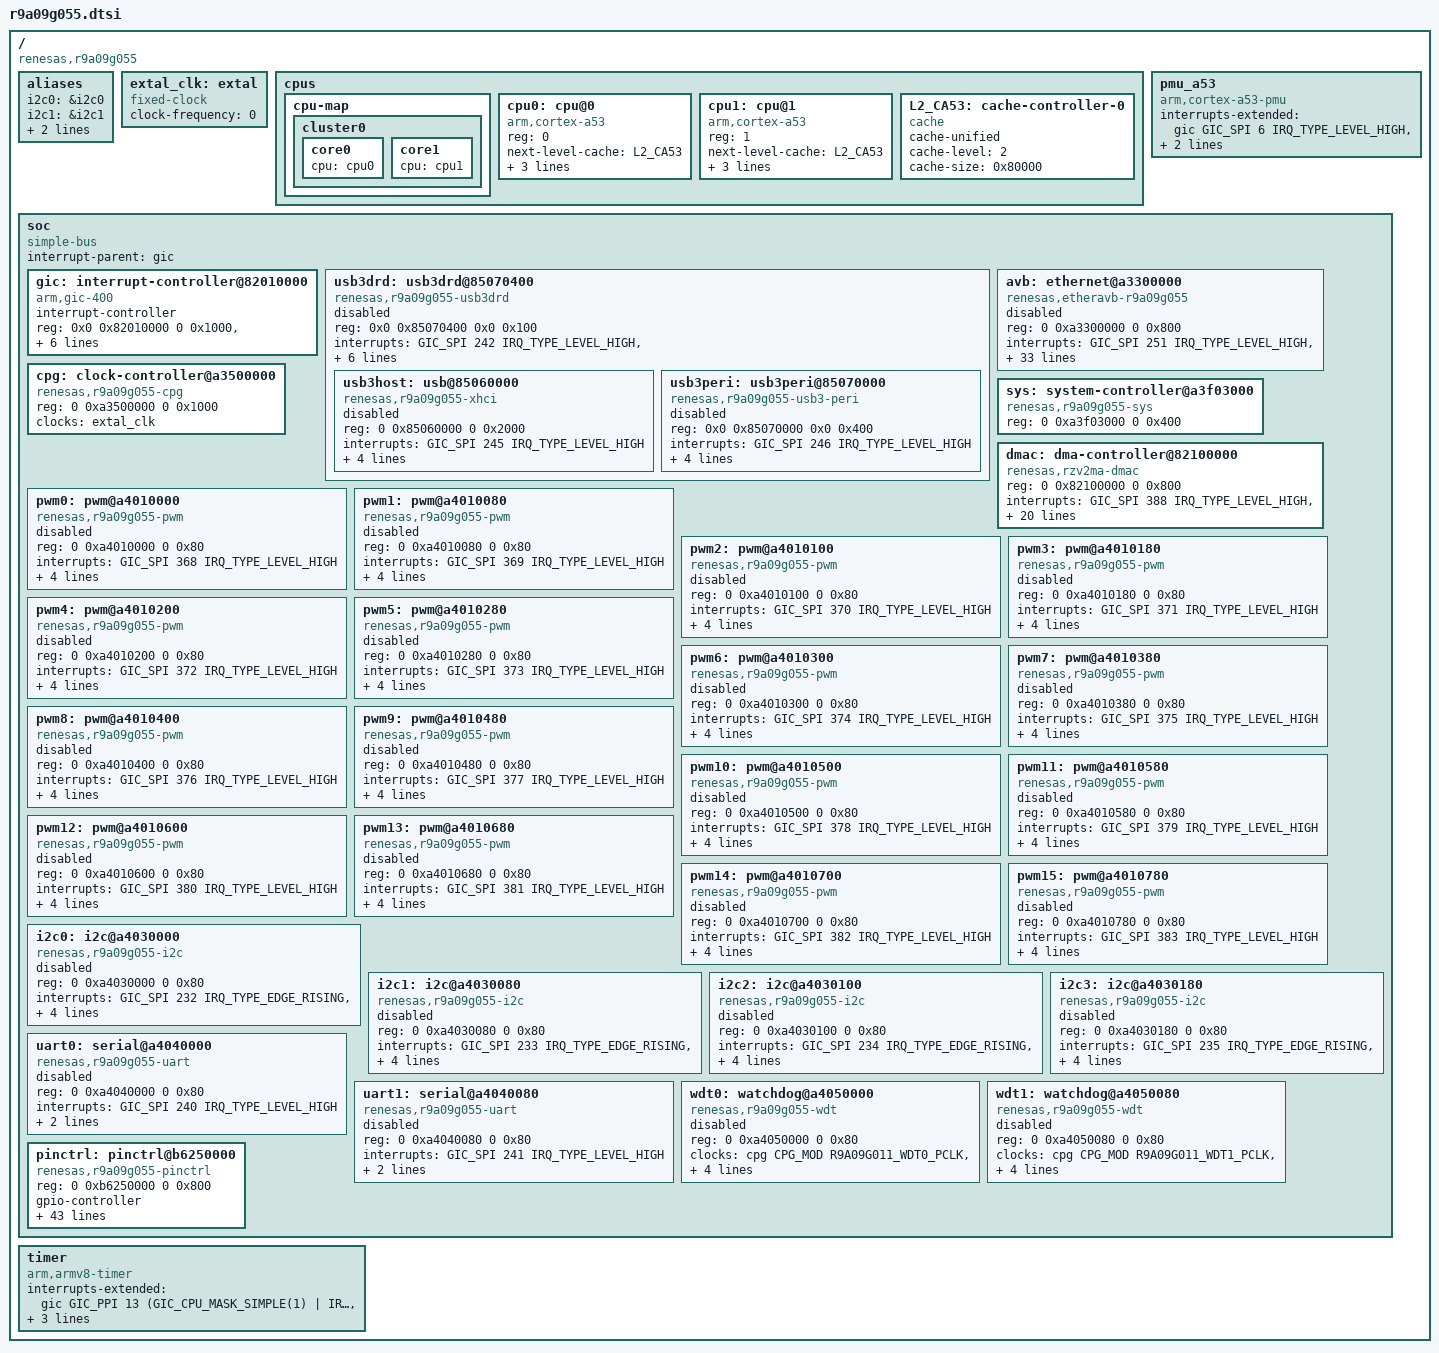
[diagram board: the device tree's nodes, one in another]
// SPDX-License-Identifier: (GPL-2.0-only OR BSD-2-Clause)
/*
 * Device Tree Source for the RZ/V2MA SoC
 *
 * Copyright (C) 2022 Renesas Electronics Corp.
 */

#include <dt-bindings/interrupt-controller/arm-gic.h>
#include <dt-bindings/clock/r9a09g011-cpg.h>

/memreserve/ 0x1B7FFF000 0x00001000; /* spin-table address */
/ {
	compatible = "renesas,r9a09g055";
	#address-cells = <2>;
	#size-cells = <2>;

        aliases {
                i2c0 = &i2c0;
                i2c1 = &i2c1;
                i2c2 = &i2c2;
                i2c3 = &i2c3;
        };

	/* clock can be either from exclk or crystal oscillator (XIN/XOUT) */
	extal_clk: extal {
		compatible = "fixed-clock";
		#clock-cells = <0>;
		/* This value must be overridden by the board */
		clock-frequency = <0>;
	};

	cpus {
		#address-cells = <1>;
		#size-cells = <0>;

		cpu-map {
			cluster0 {
				core0 {
					cpu = <&cpu0>;
				};
                                core1 {
                                        cpu = <&cpu1>;
                                };
			};
		};

		cpu0: cpu@0 {
			compatible = "arm,cortex-a53";
			reg = <0>;
			device_type = "cpu";
			next-level-cache = <&L2_CA53>;
			enable-method = "spin-table";
			cpu-release-addr = <0x1 0xB7FFF000>;
			clocks = <&cpg CPG_MOD R9A09G011_CA53_CLK>;
		};

                cpu1: cpu@1 {
                        compatible = "arm,cortex-a53";
                        reg = <1>;
                        device_type = "cpu";
			next-level-cache = <&L2_CA53>;
			enable-method = "spin-table";
			cpu-release-addr = <0x1 0xB7FFF000>;
                        clocks = <&cpg CPG_MOD R9A09G011_CA53_CLK>;
                };

		L2_CA53: cache-controller-0 {
			compatible = "cache";
			cache-unified;
			cache-level = <2>;
			cache-size = <0x80000>;
		};
	};

	pmu_a53 {
		compatible = "arm,cortex-a53-pmu";
        	interrupts-extended = <&gic GIC_SPI 6 IRQ_TYPE_LEVEL_HIGH>,
				      <&gic GIC_SPI 7 IRQ_TYPE_LEVEL_HIGH>;
        	interrupt-affinity = <&cpu0>,<&cpu1>;
    	};

	soc: soc {
		compatible = "simple-bus";
		interrupt-parent = <&gic>;
		#address-cells = <2>;
		#size-cells = <2>;
		ranges;

		gic: interrupt-controller@82010000 {
			compatible = "arm,gic-400";
			#interrupt-cells = <3>;
			#address-cells = <0>;
			interrupt-controller;
			reg = <0x0 0x82010000 0 0x1000>,
			      <0x0 0x82020000 0 0x20000>,
			      <0x0 0x82040000 0 0x20000>,
			      <0x0 0x82060000 0 0x20000>;
			interrupts = <GIC_PPI 9 (GIC_CPU_MASK_SIMPLE(1) | IRQ_TYPE_LEVEL_HIGH)>;
			clocks = <&cpg CPG_MOD R9A09G011_GIC_CLK>;
			clock-names = "clk";
		};

                usb3drd: usb3drd@85070400 {
                        compatible = "renesas,r9a09g055-usb3drd",
                                     "renesas,rzv2ma-usb3drd";
                        reg = <0x0 0x85070400 0x0 0x100>;
                        interrupts = <GIC_SPI 242 IRQ_TYPE_LEVEL_HIGH>,
                                     <GIC_SPI 243 IRQ_TYPE_LEVEL_HIGH>,
                                     <GIC_SPI 244 IRQ_TYPE_LEVEL_HIGH>;
                        interrupt-names = "drd", "bc", "gpi";
                        clocks = <&cpg CPG_MOD R9A09G011_USB_ACLK_P>,
                                 <&cpg CPG_MOD R9A09G011_USB_PCLK>;
                        clock-names = "axi", "reg";
                        resets = <&cpg R9A09G011_USB_DRD_RESET>;
                        power-domains = <&cpg>;
                        ranges;
                        #address-cells = <2>;
                        #size-cells = <2>;
                        status = "disabled";

                        usb3host: usb@85060000 {
                                compatible = "renesas,r9a09g055-xhci",
                                             "renesas,rzv2ma-xhci";
                                reg = <0 0x85060000 0 0x2000>;
                                interrupts = <GIC_SPI 245 IRQ_TYPE_LEVEL_HIGH>;
                                clocks = <&cpg CPG_MOD R9A09G011_USB_ACLK_H>,
                                         <&cpg CPG_MOD R9A09G011_USB_PCLK>;
                                clock-names = "axi", "reg";
                                resets = <&cpg R9A09G011_USB_ARESETN_H>;
                                power-domains = <&cpg>;
                                status = "disabled";
                        };

                        usb3peri: usb3peri@85070000 {
                                compatible = "renesas,r9a09g055-usb3-peri",
                                             "renesas,rzv2ma-usb3-peri";
                                reg = <0x0 0x85070000 0x0 0x400>;
                                interrupts = <GIC_SPI 246 IRQ_TYPE_LEVEL_HIGH>;
                                clocks = <&cpg CPG_MOD R9A09G011_USB_ACLK_P>,
                                         <&cpg CPG_MOD R9A09G011_USB_PCLK>;
                                clock-names = "axi", "reg";
                                resets = <&cpg R9A09G011_USB_ARESETN_P>;
                                power-domains = <&cpg>;
                                status = "disabled";
                        };
                };

		avb: ethernet@a3300000 {
			compatible = "renesas,etheravb-r9a09g055","renesas,etheravb-rzv2ma";
			reg = <0 0xa3300000 0 0x800>;
			interrupts = <GIC_SPI 251 IRQ_TYPE_LEVEL_HIGH>, /* ch0: Rx0 BE */
				     <GIC_SPI 252 IRQ_TYPE_LEVEL_HIGH>, /* ch1: Rx1 NC */
				     <GIC_SPI 253 IRQ_TYPE_LEVEL_HIGH>,
				     <GIC_SPI 254 IRQ_TYPE_LEVEL_HIGH>,
				     <GIC_SPI 255 IRQ_TYPE_LEVEL_HIGH>,
				     <GIC_SPI 256 IRQ_TYPE_LEVEL_HIGH>,
				     <GIC_SPI 257 IRQ_TYPE_LEVEL_HIGH>,
				     <GIC_SPI 258 IRQ_TYPE_LEVEL_HIGH>,
				     <GIC_SPI 259 IRQ_TYPE_LEVEL_HIGH>,
				     <GIC_SPI 260 IRQ_TYPE_LEVEL_HIGH>,
				     <GIC_SPI 261 IRQ_TYPE_LEVEL_HIGH>,
				     <GIC_SPI 262 IRQ_TYPE_LEVEL_HIGH>,
				     <GIC_SPI 263 IRQ_TYPE_LEVEL_HIGH>,
				     <GIC_SPI 264 IRQ_TYPE_LEVEL_HIGH>,
				     <GIC_SPI 265 IRQ_TYPE_LEVEL_HIGH>,
				     <GIC_SPI 266 IRQ_TYPE_LEVEL_HIGH>,
				     <GIC_SPI 267 IRQ_TYPE_LEVEL_HIGH>,
				     <GIC_SPI 268 IRQ_TYPE_LEVEL_HIGH>,
				     <GIC_SPI 269 IRQ_TYPE_LEVEL_HIGH>, /* ch18: Tx0 BE */
				     <GIC_SPI 270 IRQ_TYPE_LEVEL_HIGH>, /* ch19: Tx1 NC */
				     <GIC_SPI 271 IRQ_TYPE_LEVEL_HIGH>,
				     <GIC_SPI 272 IRQ_TYPE_LEVEL_HIGH>,
				     <GIC_SPI 273 IRQ_TYPE_LEVEL_HIGH>, /* DiA */
				     <GIC_SPI 274 IRQ_TYPE_LEVEL_HIGH>, /* DiB */
				     <GIC_SPI 275 IRQ_TYPE_LEVEL_HIGH>, /* Line1_A */
				     <GIC_SPI 276 IRQ_TYPE_LEVEL_HIGH>, /* Line1_B */
				     <GIC_SPI 277 IRQ_TYPE_LEVEL_HIGH>, /* Line2_A */
				     <GIC_SPI 278 IRQ_TYPE_LEVEL_HIGH>, /* Line2_B */
				     <GIC_SPI 279 IRQ_TYPE_LEVEL_HIGH>; /* Line3 MAC */
			interrupt-names = "ch0", "ch1", "ch2", "ch3",
					  "ch4", "ch5", "ch6", "ch7",
					  "ch8", "ch9", "ch10", "ch11",
					  "ch12", "ch13", "ch14", "ch15",
					  "ch16", "ch17", "ch18", "ch19",
					  "ch20", "ch21", "dia", "dib",
					  "err_a", "err_b", "mgmt_a", "mgmt_b",
					  "line3";
			clocks = <&cpg CPG_MOD R9A09G011_ETH0_CLK_AXI>,
				 <&cpg CPG_MOD R9A09G011_ETH0_CLK_CHI>,
				 <&cpg CPG_MOD R9A09G011_ETH0_GPTP_EXT>;
			clock-names = "axi", "chi", "gptp";
			resets = <&cpg R9A09G011_ETH0_RST_HW_N>;
			power-domains = <&cpg>;
			#address-cells = <1>;
			#size-cells = <0>;
			status = "disabled";
		};

		cpg: clock-controller@a3500000 {
			compatible = "renesas,r9a09g055-cpg";
			reg = <0 0xa3500000 0 0x1000>;
			clocks = <&extal_clk>;
			clock-names = "extal";
			#clock-cells = <2>;
			#reset-cells = <1>;
			#power-domain-cells = <0>;
		};

		sys: system-controller@a3f03000 {
			compatible = "renesas,r9a09g055-sys";
			reg = <0 0xa3f03000 0 0x400>;
		};

		dmac: dma-controller@82100000 {
			compatible = "renesas,rzv2ma-dmac",
                                     "renesas,r9a09g055-dmac";
                    	reg = <0 0x82100000 0 0x800>;
                    	interrupts = <GIC_SPI 388 IRQ_TYPE_LEVEL_HIGH>,
                                     <GIC_SPI 50 IRQ_TYPE_LEVEL_HIGH>,
                                     <GIC_SPI 51 IRQ_TYPE_LEVEL_HIGH>,
                                     <GIC_SPI 52 IRQ_TYPE_LEVEL_HIGH>,
                                     <GIC_SPI 53 IRQ_TYPE_LEVEL_HIGH>,
                                     <GIC_SPI 54 IRQ_TYPE_LEVEL_HIGH>,
                                     <GIC_SPI 55 IRQ_TYPE_LEVEL_HIGH>,
                                     <GIC_SPI 56 IRQ_TYPE_LEVEL_HIGH>,
                                     <GIC_SPI 57 IRQ_TYPE_LEVEL_HIGH>,
                                     <GIC_SPI 58 IRQ_TYPE_LEVEL_HIGH>,
                                     <GIC_SPI 59 IRQ_TYPE_LEVEL_HIGH>,
                                     <GIC_SPI 60 IRQ_TYPE_LEVEL_HIGH>,
                                     <GIC_SPI 61 IRQ_TYPE_LEVEL_HIGH>,
                                     <GIC_SPI 62 IRQ_TYPE_LEVEL_HIGH>,
                                     <GIC_SPI 63 IRQ_TYPE_LEVEL_HIGH>,
                                     <GIC_SPI 64 IRQ_TYPE_LEVEL_HIGH>,
                                     <GIC_SPI 65 IRQ_TYPE_LEVEL_HIGH>;

	                    interrupt-names = "error",
	                                    "ch0", "ch1", "ch2", "ch3",
	                                    "ch4", "ch5", "ch6", "ch7",
	                                    "ch8", "ch9", "ch10", "ch11",
	                                    "ch12", "ch13", "ch14", "ch15";
	                    clocks = <&cpg CPG_MOD R9A09G011_DMAA_ACLK>;
	                    clock-names = "dmaa_aclk";
	                    power-domains = <&cpg>;
	                    resets = <&cpg R9A09G011_DMAA_ARESETN>;
	                    #dma-cells = <1>;
	                    dma-channels = <16>;
		};

                pwm0: pwm@a4010000 {
                        compatible = "renesas,r9a09g055-pwm",
                                     "renesas,rzv2ma-pwm";
                        reg = <0 0xa4010000 0 0x80>;
                        interrupts = <GIC_SPI 368 IRQ_TYPE_LEVEL_HIGH>;
                        clocks = <&cpg CPG_MOD R9A09G011_CPERI_GRPE_PCLK>,
                                 <&cpg CPG_MOD R9A09G011_PWM0_CLK>;
                        clock-names = "apb", "pwm";
                        resets = <&cpg R9A09G011_PWM_GPE_PRESETN>;
                        power-domains = <&cpg>;
                        #pwm-cells = <2>;
                        status = "disabled";
                };

                pwm1: pwm@a4010080 {
                        compatible = "renesas,r9a09g055-pwm",
                                     "renesas,rzv2ma-pwm";
                        reg = <0 0xa4010080 0 0x80>;
                        interrupts = <GIC_SPI 369 IRQ_TYPE_LEVEL_HIGH>;
                        clocks = <&cpg CPG_MOD R9A09G011_CPERI_GRPE_PCLK>,
                                 <&cpg CPG_MOD R9A09G011_PWM1_CLK>;
                        clock-names = "apb", "pwm";
                        resets = <&cpg R9A09G011_PWM_GPE_PRESETN>;
                        power-domains = <&cpg>;
                        #pwm-cells = <2>;
                        status = "disabled";
                };

                pwm2: pwm@a4010100 {
                        compatible = "renesas,r9a09g055-pwm",
                                     "renesas,rzv2ma-pwm";
                        reg = <0 0xa4010100 0 0x80>;
                        interrupts = <GIC_SPI 370 IRQ_TYPE_LEVEL_HIGH>;
                        clocks = <&cpg CPG_MOD R9A09G011_CPERI_GRPE_PCLK>,
                                 <&cpg CPG_MOD R9A09G011_PWM2_CLK>;
                        clock-names = "apb", "pwm";
                        resets = <&cpg R9A09G011_PWM_GPE_PRESETN>;
                        power-domains = <&cpg>;
                        #pwm-cells = <2>;
                        status = "disabled";
                };

                pwm3: pwm@a4010180 {
                        compatible = "renesas,r9a09g055-pwm",
                                     "renesas,rzv2ma-pwm";
                        reg = <0 0xa4010180 0 0x80>;
                        interrupts = <GIC_SPI 371 IRQ_TYPE_LEVEL_HIGH>;
                        clocks = <&cpg CPG_MOD R9A09G011_CPERI_GRPE_PCLK>,
                                 <&cpg CPG_MOD R9A09G011_PWM3_CLK>;
                        clock-names = "apb", "pwm";
                        resets = <&cpg R9A09G011_PWM_GPE_PRESETN>;
                        power-domains = <&cpg>;
                        #pwm-cells = <2>;
                        status = "disabled";
                };

                pwm4: pwm@a4010200 {
                        compatible = "renesas,r9a09g055-pwm",
                                     "renesas,rzv2ma-pwm";
                        reg = <0 0xa4010200 0 0x80>;
                        interrupts = <GIC_SPI 372 IRQ_TYPE_LEVEL_HIGH>;
                        clocks = <&cpg CPG_MOD R9A09G011_CPERI_GRPE_PCLK>,
                                 <&cpg CPG_MOD R9A09G011_PWM4_CLK>;
                        clock-names = "apb", "pwm";
                        resets = <&cpg R9A09G011_PWM_GPE_PRESETN>;
                        power-domains = <&cpg>;
                        #pwm-cells = <2>;
                        status = "disabled";
                };

                pwm5: pwm@a4010280 {
                        compatible = "renesas,r9a09g055-pwm",
                                     "renesas,rzv2ma-pwm";
                        reg = <0 0xa4010280 0 0x80>;
                        interrupts = <GIC_SPI 373 IRQ_TYPE_LEVEL_HIGH>;
                        clocks = <&cpg CPG_MOD R9A09G011_CPERI_GRPE_PCLK>,
                                 <&cpg CPG_MOD R9A09G011_PWM5_CLK>;
                        clock-names = "apb", "pwm";
                        resets = <&cpg R9A09G011_PWM_GPE_PRESETN>;
                        power-domains = <&cpg>;
                        #pwm-cells = <2>;
                        status = "disabled";
                };

                pwm6: pwm@a4010300 {
                        compatible = "renesas,r9a09g055-pwm",
                                     "renesas,rzv2ma-pwm";
                        reg = <0 0xa4010300 0 0x80>;
                        interrupts = <GIC_SPI 374 IRQ_TYPE_LEVEL_HIGH>;
                        clocks = <&cpg CPG_MOD R9A09G011_CPERI_GRPE_PCLK>,
                                 <&cpg CPG_MOD R9A09G011_PWM6_CLK>;
                        clock-names = "apb", "pwm";
                        resets = <&cpg R9A09G011_PWM_GPE_PRESETN>;
                        power-domains = <&cpg>;
                        #pwm-cells = <2>;
                        status = "disabled";
                };

                pwm7: pwm@a4010380 {
                        compatible = "renesas,r9a09g055-pwm",
                                     "renesas,rzv2ma-pwm";
                        reg = <0 0xa4010380 0 0x80>;
                        interrupts = <GIC_SPI 375 IRQ_TYPE_LEVEL_HIGH>;
                        clocks = <&cpg CPG_MOD R9A09G011_CPERI_GRPE_PCLK>,
                                 <&cpg CPG_MOD R9A09G011_PWM7_CLK>;
                        clock-names = "apb", "pwm";
                        resets = <&cpg R9A09G011_PWM_GPE_PRESETN>;
                        power-domains = <&cpg>;
                        #pwm-cells = <2>;
                        status = "disabled";
                };

		pwm8: pwm@a4010400 {
			compatible = "renesas,r9a09g055-pwm",
				     "renesas,rzv2ma-pwm";
			reg = <0 0xa4010400 0 0x80>;
			interrupts = <GIC_SPI 376 IRQ_TYPE_LEVEL_HIGH>;
			clocks = <&cpg CPG_MOD R9A09G011_CPERI_GRPF_PCLK>,
				 <&cpg CPG_MOD R9A09G011_PWM8_CLK>;
			clock-names = "apb", "pwm";
			resets = <&cpg R9A09G011_PWM_GPF_PRESETN>;
			power-domains = <&cpg>;
			#pwm-cells = <2>;
			status = "disabled";
		};

		pwm9: pwm@a4010480 {
			compatible = "renesas,r9a09g055-pwm",
				     "renesas,rzv2ma-pwm";
			reg = <0 0xa4010480 0 0x80>;
			interrupts = <GIC_SPI 377 IRQ_TYPE_LEVEL_HIGH>;
			clocks = <&cpg CPG_MOD R9A09G011_CPERI_GRPF_PCLK>,
				 <&cpg CPG_MOD R9A09G011_PWM9_CLK>;
			clock-names = "apb", "pwm";
			resets = <&cpg R9A09G011_PWM_GPF_PRESETN>;
			power-domains = <&cpg>;
			#pwm-cells = <2>;
			status = "disabled";
		};

		pwm10: pwm@a4010500 {
			compatible = "renesas,r9a09g055-pwm",
				     "renesas,rzv2ma-pwm";
			reg = <0 0xa4010500 0 0x80>;
			interrupts = <GIC_SPI 378 IRQ_TYPE_LEVEL_HIGH>;
			clocks = <&cpg CPG_MOD R9A09G011_CPERI_GRPF_PCLK>,
				 <&cpg CPG_MOD R9A09G011_PWM10_CLK>;
			clock-names = "apb", "pwm";
			resets = <&cpg R9A09G011_PWM_GPF_PRESETN>;
			power-domains = <&cpg>;
			#pwm-cells = <2>;
			status = "disabled";
		};

		pwm11: pwm@a4010580 {
			compatible = "renesas,r9a09g055-pwm",
				     "renesas,rzv2ma-pwm";
			reg = <0 0xa4010580 0 0x80>;
			interrupts = <GIC_SPI 379 IRQ_TYPE_LEVEL_HIGH>;
			clocks = <&cpg CPG_MOD R9A09G011_CPERI_GRPF_PCLK>,
				 <&cpg CPG_MOD R9A09G011_PWM11_CLK>;
			clock-names = "apb", "pwm";
			resets = <&cpg R9A09G011_PWM_GPF_PRESETN>;
			power-domains = <&cpg>;
			#pwm-cells = <2>;
			status = "disabled";
		};

		pwm12: pwm@a4010600 {
			compatible = "renesas,r9a09g055-pwm",
				     "renesas,rzv2ma-pwm";
			reg = <0 0xa4010600 0 0x80>;
			interrupts = <GIC_SPI 380 IRQ_TYPE_LEVEL_HIGH>;
			clocks = <&cpg CPG_MOD R9A09G011_CPERI_GRPF_PCLK>,
				 <&cpg CPG_MOD R9A09G011_PWM12_CLK>;
			clock-names = "apb", "pwm";
			resets = <&cpg R9A09G011_PWM_GPF_PRESETN>;
			power-domains = <&cpg>;
			#pwm-cells = <2>;
			status = "disabled";
		};

		pwm13: pwm@a4010680 {
			compatible = "renesas,r9a09g055-pwm",
				     "renesas,rzv2ma-pwm";
			reg = <0 0xa4010680 0 0x80>;
			interrupts = <GIC_SPI 381 IRQ_TYPE_LEVEL_HIGH>;
			clocks = <&cpg CPG_MOD R9A09G011_CPERI_GRPF_PCLK>,
				 <&cpg CPG_MOD R9A09G011_PWM13_CLK>;
			clock-names = "apb", "pwm";
			resets = <&cpg R9A09G011_PWM_GPF_PRESETN>;
			power-domains = <&cpg>;
			#pwm-cells = <2>;
			status = "disabled";
		};

		pwm14: pwm@a4010700 {
			compatible = "renesas,r9a09g055-pwm",
				     "renesas,rzv2ma-pwm";
			reg = <0 0xa4010700 0 0x80>;
			interrupts = <GIC_SPI 382 IRQ_TYPE_LEVEL_HIGH>;
			clocks = <&cpg CPG_MOD R9A09G011_CPERI_GRPF_PCLK>,
				 <&cpg CPG_MOD R9A09G011_PWM14_CLK>;
			clock-names = "apb", "pwm";
			resets = <&cpg R9A09G011_PWM_GPF_PRESETN>;
			power-domains = <&cpg>;
			#pwm-cells = <2>;
			status = "disabled";
		};

                pwm15: pwm@a4010780 {
                        compatible = "renesas,r9a09g055-pwm",
                                     "renesas,rzv2ma-pwm";
                        reg = <0 0xa4010780 0 0x80>;
                        interrupts = <GIC_SPI 383 IRQ_TYPE_LEVEL_HIGH>;
                        clocks = <&cpg CPG_MOD R9A09G011_CPERI_GRPF_PCLK>,
                                 <&cpg CPG_MOD R9A09G011_PWM15_CLK>;
                        clock-names = "apb", "pwm";
                        resets = <&cpg R9A09G011_PWM_GPF_PRESETN>;
                        power-domains = <&cpg>;
                        #pwm-cells = <2>;
                        status = "disabled";
                };

		i2c0: i2c@a4030000 {
			#address-cells = <1>;
			#size-cells = <0>;
			compatible = "renesas,r9a09g055-i2c", "renesas,rzv2ma-i2c";
			reg = <0 0xa4030000 0 0x80>;
			interrupts = <GIC_SPI 232 IRQ_TYPE_EDGE_RISING>,
				     <GIC_SPI 236 IRQ_TYPE_EDGE_RISING>;
			interrupt-names = "tia", "tis";
			clocks = <&cpg CPG_MOD R9A09G011_IIC_PCLK0>;
			resets = <&cpg R9A09G011_IIC_GPA_PRESETN>;
			power-domains = <&cpg>;
			status = "disabled";
		};

		i2c1: i2c@a4030080 {
			#address-cells = <1>;
			#size-cells = <0>;
			compatible = "renesas,r9a09g055-i2c", "renesas,rzv2ma-i2c";
			reg = <0 0xa4030080 0 0x80>;
			interrupts = <GIC_SPI 233 IRQ_TYPE_EDGE_RISING>,
				     <GIC_SPI 237 IRQ_TYPE_EDGE_RISING>;
			interrupt-names = "tia", "tis";
			clocks = <&cpg CPG_MOD R9A09G011_IIC_PCLK0>;
			resets = <&cpg R9A09G011_IIC_GPA_PRESETN>;
			power-domains = <&cpg>;
			status = "disabled";
		};

                i2c2: i2c@a4030100 {
                        #address-cells = <1>;
                        #size-cells = <0>;
                        compatible = "renesas,r9a09g055-i2c", "renesas,rzv2ma-i2c";
                        reg = <0 0xa4030100 0 0x80>;
                        interrupts = <GIC_SPI 234 IRQ_TYPE_EDGE_RISING>,
                                     <GIC_SPI 238 IRQ_TYPE_EDGE_RISING>;
                        interrupt-names = "tia", "tis";
                        clocks = <&cpg CPG_MOD R9A09G011_IIC_PCLK1>;
                        resets = <&cpg R9A09G011_IIC_GPB_PRESETN>;
                        power-domains = <&cpg>;
                        status = "disabled";
                };

                i2c3: i2c@a4030180 {
                        #address-cells = <1>;
                        #size-cells = <0>;
                        compatible = "renesas,r9a09g055-i2c", "renesas,rzv2ma-i2c";
                        reg = <0 0xa4030180 0 0x80>;
                        interrupts = <GIC_SPI 235 IRQ_TYPE_EDGE_RISING>,
                                     <GIC_SPI 239 IRQ_TYPE_EDGE_RISING>;
                        interrupt-names = "tia", "tis";
                        clocks = <&cpg CPG_MOD R9A09G011_IIC_PCLK1>;
                        resets = <&cpg R9A09G011_IIC_GPB_PRESETN>;
                        power-domains = <&cpg>;
                        status = "disabled";
                };

		uart0: serial@a4040000 {
			compatible = "renesas,r9a09g055-uart", "renesas,em-uart";
			reg = <0 0xa4040000 0 0x80>;
			interrupts = <GIC_SPI 240 IRQ_TYPE_LEVEL_HIGH>;
			clocks = <&cpg CPG_MOD R9A09G011_URT0_CLK>,
				 <&cpg CPG_MOD R9A09G011_URT_PCLK>;
			clock-names = "sclk", "pclk";
			status = "disabled";
		};

                uart1: serial@a4040080 {
                        compatible = "renesas,r9a09g055-uart", "renesas,em-uart";
                        reg = <0 0xa4040080 0 0x80>;
                        interrupts = <GIC_SPI 241 IRQ_TYPE_LEVEL_HIGH>;
                        clocks = <&cpg CPG_MOD R9A09G011_URT1_CLK>,
                                 <&cpg CPG_MOD R9A09G011_URT_PCLK>;
                        clock-names = "sclk", "pclk";
                        status = "disabled";
                };

		wdt0: watchdog@a4050000 {
			compatible = "renesas,r9a09g055-wdt",
				     "renesas,rzv2ma-wdt";
			reg = <0 0xa4050000 0 0x80>;
			clocks = <&cpg CPG_MOD R9A09G011_WDT0_PCLK>,
				 <&cpg CPG_MOD R9A09G011_WDT0_CLK>;
			clock-names = "pclk", "oscclk";
			interrupts = <GIC_SPI 43 IRQ_TYPE_LEVEL_HIGH>;
			resets = <&cpg R9A09G011_WDT0_PRESETN>;
			power-domains = <&cpg>;
			status = "disabled";
		};

                wdt1: watchdog@a4050080 {
                        compatible = "renesas,r9a09g055-wdt",
                                     "renesas,rzv2ma-wdt";
                        reg = <0 0xa4050080 0 0x80>;
                        clocks = <&cpg CPG_MOD R9A09G011_WDT1_PCLK>,
                                 <&cpg CPG_MOD R9A09G011_WDT1_CLK>;
                        clock-names = "pclk", "oscclk";
                        interrupts = <GIC_SPI 44 IRQ_TYPE_LEVEL_HIGH>;
                        resets = <&cpg R9A09G011_WDT1_PRESETN>;
                        power-domains = <&cpg>;
                        status = "disabled";
                };

		pinctrl: pinctrl@b6250000 {
			compatible = "renesas,r9a09g055-pinctrl";
			reg = <0 0xb6250000 0 0x800>;
			gpio-controller;
			#gpio-cells = <2>;
			gpio-ranges = <&pinctrl 0 0 352>;
			interrupts = <GIC_SPI 68 IRQ_TYPE_LEVEL_HIGH>,
				     <GIC_SPI 69 IRQ_TYPE_LEVEL_HIGH>,
				     <GIC_SPI 70 IRQ_TYPE_LEVEL_HIGH>,
				     <GIC_SPI 71 IRQ_TYPE_LEVEL_HIGH>,
				     <GIC_SPI 72 IRQ_TYPE_LEVEL_HIGH>,
				     <GIC_SPI 73 IRQ_TYPE_LEVEL_HIGH>,
				     <GIC_SPI 74 IRQ_TYPE_LEVEL_HIGH>,
				     <GIC_SPI 75 IRQ_TYPE_LEVEL_HIGH>,
				     <GIC_SPI 76 IRQ_TYPE_LEVEL_HIGH>,
				     <GIC_SPI 77 IRQ_TYPE_LEVEL_HIGH>,
				     <GIC_SPI 78 IRQ_TYPE_LEVEL_HIGH>,
				     <GIC_SPI 79 IRQ_TYPE_LEVEL_HIGH>,
				     <GIC_SPI 80 IRQ_TYPE_LEVEL_HIGH>,
				     <GIC_SPI 81 IRQ_TYPE_LEVEL_HIGH>,
				     <GIC_SPI 82 IRQ_TYPE_LEVEL_HIGH>,
				     <GIC_SPI 83 IRQ_TYPE_LEVEL_HIGH>,
				     <GIC_SPI 84 IRQ_TYPE_LEVEL_HIGH>,
				     <GIC_SPI 85 IRQ_TYPE_LEVEL_HIGH>,
				     <GIC_SPI 86 IRQ_TYPE_LEVEL_HIGH>,
				     <GIC_SPI 87 IRQ_TYPE_LEVEL_HIGH>,
				     <GIC_SPI 88 IRQ_TYPE_LEVEL_HIGH>,
				     <GIC_SPI 89 IRQ_TYPE_LEVEL_HIGH>,
				     <GIC_SPI 90 IRQ_TYPE_LEVEL_HIGH>,
				     <GIC_SPI 91 IRQ_TYPE_LEVEL_HIGH>,
				     <GIC_SPI 92 IRQ_TYPE_LEVEL_HIGH>,
				     <GIC_SPI 93 IRQ_TYPE_LEVEL_HIGH>,
				     <GIC_SPI 94 IRQ_TYPE_LEVEL_HIGH>,
				     <GIC_SPI 95 IRQ_TYPE_LEVEL_HIGH>,
				     <GIC_SPI 96 IRQ_TYPE_LEVEL_HIGH>,
				     <GIC_SPI 97 IRQ_TYPE_LEVEL_HIGH>,
				     <GIC_SPI 98 IRQ_TYPE_LEVEL_HIGH>,
				     <GIC_SPI 99 IRQ_TYPE_LEVEL_HIGH>,
				     <GIC_SPI 100 IRQ_TYPE_LEVEL_HIGH>,
				     <GIC_SPI 101 IRQ_TYPE_LEVEL_HIGH>,
				     <GIC_SPI 102 IRQ_TYPE_LEVEL_HIGH>,
				     <GIC_SPI 103 IRQ_TYPE_LEVEL_HIGH>,
				     <GIC_SPI 104 IRQ_TYPE_LEVEL_HIGH>,
				     <GIC_SPI 105 IRQ_TYPE_LEVEL_HIGH>,
				     <GIC_SPI 106 IRQ_TYPE_LEVEL_HIGH>;
			clocks = <&cpg CPG_MOD R9A09G011_PFC_PCLK>;
			power-domains = <&cpg>;
			resets = <&cpg R9A09G011_PFC_PRESETN>;
		};
	};

	timer {
		compatible = "arm,armv8-timer";
		interrupts-extended = <&gic GIC_PPI 13 (GIC_CPU_MASK_SIMPLE(1) | IRQ_TYPE_LEVEL_LOW)>,
				      <&gic GIC_PPI 14 (GIC_CPU_MASK_SIMPLE(1) | IRQ_TYPE_LEVEL_LOW)>,
				      <&gic GIC_PPI 11 (GIC_CPU_MASK_SIMPLE(1) | IRQ_TYPE_LEVEL_LOW)>,
				      <&gic GIC_PPI 10 (GIC_CPU_MASK_SIMPLE(1) | IRQ_TYPE_LEVEL_LOW)>;
	};
};
